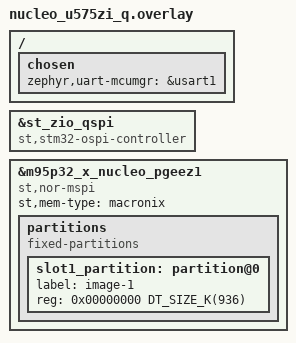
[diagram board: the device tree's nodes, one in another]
/*
 * SPDX-FileCopyrightText: Copyright 2026 EXALT Technologies
 *
 * SPDX-License-Identifier: Apache-2.0
 */

#include <mem.h>

/ {
	chosen {
		zephyr,uart-mcumgr = &usart1;
	};
};

/delete-node/ &slot1_partition;

&st_zio_qspi {
	compatible = "st,stm32-ospi-controller";
};

&m95p32_x_nucleo_pgeez1 {
	compatible = "st,nor-mspi", "jedec,nor";
	st,mem-type = "macronix";

	partitions {
		compatible = "fixed-partitions";
		#address-cells = <1>;
		#size-cells = <1>;

		slot1_partition: partition@0 {
			label = "image-1";
			/* 116 image sectors plus one 8-KiB offset-swap sector. */
			reg = <0x00000000 DT_SIZE_K(936)>;
		};
	};
};
